AUTOSAR XML (schema 3.1.2)
package /Components/SWC_ProdElEng
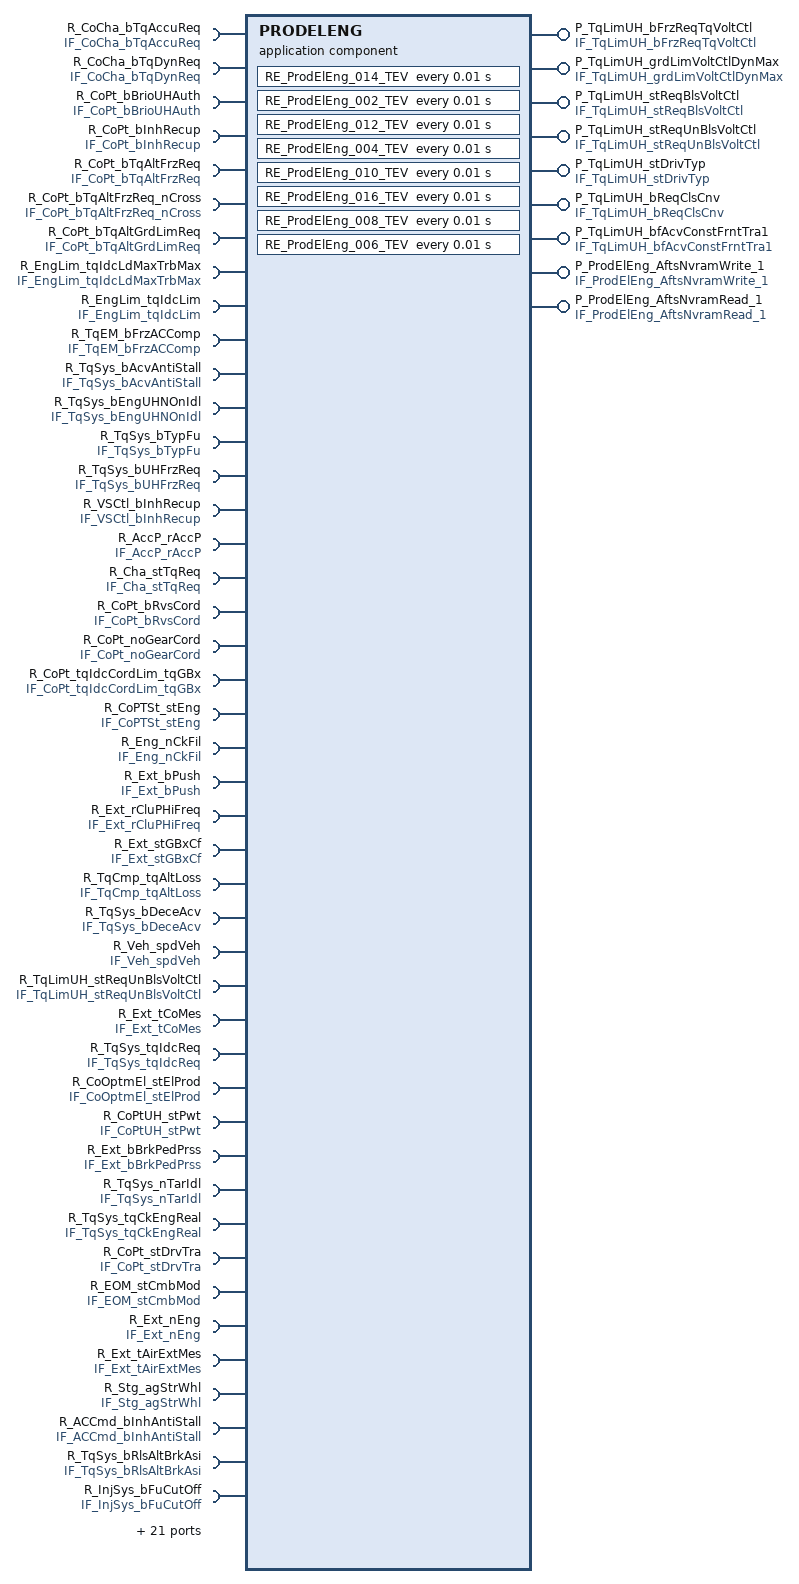
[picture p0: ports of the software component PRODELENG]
  application software component type PRODELENG
    63 x require port:
      R_CoCha_bTqAccuReq: unqueued-receiver-com-spec{data-element=CoCha_bTqAccuReq, init-value=ConstantValue, resync-time=0}, required-interface=IF_CoCha_bTqAccuReq
      R_CoCha_bTqDynReq: unqueued-receiver-com-spec{data-element=CoCha_bTqDynReq, init-value=ConstantValue1, resync-time=0}, required-interface=IF_CoCha_bTqDynReq
      R_CoPt_bBrioUHAuth: unqueued-receiver-com-spec{data-element=CoPt_bBrioUHAuth, init-value=CoPt_bBrioUHAuth_in, resync-time=0}, required-interface=IF_CoPt_bBrioUHAuth
      R_CoPt_bInhRecup: unqueued-receiver-com-spec{data-element=CoPt_bInhRecup, init-value=CoPt_bInhRecup_in, resync-time=0}, required-interface=IF_CoPt_bInhRecup
      R_CoPt_bTqAltFrzReq: unqueued-receiver-com-spec{data-element=CoPt_bTqAltFrzReq, init-value=CoPt_bTqAltFrzReq_in, resync-time=0}, required-interface=IF_CoPt_bTqAltFrzReq
      R_CoPt_bTqAltFrzReq_nCross: unqueued-receiver-com-spec{data-element=CoPt_bTqAltFrzReq_nCross, init-value=CoPt_bTqAltFrzReq_nCross_in, resync-time=0}, required-interface=IF_CoPt_bTqAltFrzReq_nCross
      R_CoPt_bTqAltGrdLimReq: unqueued-receiver-com-spec{data-element=CoPt_bTqAltGrdLimReq, init-value=CoPt_bTqAltGrdLimReq_in, resync-time=0}, required-interface=IF_CoPt_bTqAltGrdLimReq
      R_EngLim_tqIdcLdMaxTrbMax: unqueued-receiver-com-spec{data-element=EngLim_tqIdcLdMaxTrbMax, init-value=ConstantValue3, resync-time=0}, required-interface=IF_EngLim_tqIdcLdMaxTrbMax
      R_EngLim_tqIdcLim: unqueued-receiver-com-spec{data-element=EngLim_tqIdcLim, init-value=ConstantValue5, resync-time=0}, required-interface=IF_EngLim_tqIdcLim
      R_TqEM_bFrzACComp: unqueued-receiver-com-spec{data-element=TqEM_bFrzACComp, init-value=ConstantValue7, resync-time=0}, required-interface=IF_TqEM_bFrzACComp
      R_TqSys_bAcvAntiStall: unqueued-receiver-com-spec{data-element=TqSys_bAcvAntiStall, init-value=ConstantValue9, resync-time=0}, required-interface=IF_TqSys_bAcvAntiStall
      R_TqSys_bEngUHNOnIdl: unqueued-receiver-com-spec{data-element=TqSys_bEngUHNOnIdl, init-value=ConstantValue11, resync-time=0}, required-interface=IF_TqSys_bEngUHNOnIdl
      R_TqSys_bTypFu: unqueued-receiver-com-spec{data-element=TqSys_bTypFu, init-value=ConstantValue13, resync-time=0}, required-interface=IF_TqSys_bTypFu
      R_TqSys_bUHFrzReq: unqueued-receiver-com-spec{data-element=TqSys_bUHFrzReq, init-value=ConstantValue15, resync-time=0}, required-interface=IF_TqSys_bUHFrzReq
      R_VSCtl_bInhRecup: unqueued-receiver-com-spec{data-element=VSCtl_bInhRecup, init-value=VSCtl_bInhRecup_in, resync-time=0}, required-interface=IF_VSCtl_bInhRecup
      R_AccP_rAccP: unqueued-receiver-com-spec{data-element=AccP_rAccP, init-value=ConstantValue17, resync-time=0}, required-interface=IF_AccP_rAccP
      R_Cha_stTqReq: unqueued-receiver-com-spec{data-element=Cha_stTqReq, init-value=ConstantValue19, resync-time=0}, required-interface=IF_Cha_stTqReq
      R_CoPt_bRvsCord: unqueued-receiver-com-spec{data-element=CoPt_bRvsCord, init-value=ConstantValue21, resync-time=0}, required-interface=IF_CoPt_bRvsCord
      R_CoPt_noGearCord: unqueued-receiver-com-spec{data-element=CoPt_noGearCord, init-value=ConstantValue23, resync-time=0}, required-interface=IF_CoPt_noGearCord
      R_CoPt_tqIdcCordLim_tqGBx: unqueued-receiver-com-spec{data-element=CoPt_tqIdcCordLim_tqGBx, init-value=ConstantValue25, resync-time=0}, required-interface=IF_CoPt_tqIdcCordLim_tqGBx
      R_CoPTSt_stEng: unqueued-receiver-com-spec{data-element=CoPTSt_stEng, init-value=ConstantValue27, resync-time=0}, required-interface=IF_CoPTSt_stEng
      R_Eng_nCkFil: unqueued-receiver-com-spec{data-element=Eng_nCkFil, init-value=ConstantValue29, resync-time=0}, required-interface=IF_Eng_nCkFil
      R_Ext_bPush: unqueued-receiver-com-spec{data-element=Ext_bPush, init-value=ConstantValue31, resync-time=0}, required-interface=IF_Ext_bPush
      R_Ext_rCluPHiFreq: unqueued-receiver-com-spec{data-element=Ext_rCluPHiFreq, init-value=ConstantValue33, resync-time=0}, required-interface=IF_Ext_rCluPHiFreq
      R_Ext_stGBxCf: unqueued-receiver-com-spec{data-element=Ext_stGBxCf, init-value=ConstantValue35, resync-time=0}, required-interface=IF_Ext_stGBxCf
      R_TqCmp_tqAltLoss: unqueued-receiver-com-spec{data-element=TqCmp_tqAltLoss, init-value=ConstantValue37, resync-time=0}, required-interface=IF_TqCmp_tqAltLoss
      R_TqSys_bDeceAcv: unqueued-receiver-com-spec{data-element=TqSys_bDeceAcv, init-value=ConstantValue39, resync-time=0}, required-interface=IF_TqSys_bDeceAcv
      R_Veh_spdVeh: unqueued-receiver-com-spec{data-element=Veh_spdVeh, init-value=ConstantValue41, resync-time=0}, required-interface=IF_Veh_spdVeh
      R_TqLimUH_stReqUnBlsVoltCtl: unqueued-receiver-com-spec{data-element=TqLimUH_stReqUnBlsVoltCtl, init-value=ConstantValue43, resync-time=0}, required-interface=IF_TqLimUH_stReqUnBlsVoltCtl
      R_Ext_tCoMes: unqueued-receiver-com-spec{data-element=Ext_tCoMes, init-value=ConstantValue45, resync-time=0}, required-interface=IF_Ext_tCoMes
      R_TqSys_tqIdcReq: unqueued-receiver-com-spec{data-element=TqSys_tqIdcReq, init-value=ConstantValue47, resync-time=0}, required-interface=IF_TqSys_tqIdcReq
      R_CoOptmEl_stElProd: unqueued-receiver-com-spec{data-element=CoOptmEl_stElProd, init-value=ConstantValue49, resync-time=0}, required-interface=IF_CoOptmEl_stElProd
      R_CoPtUH_stPwt: unqueued-receiver-com-spec{data-element=CoPtUH_stPwt, init-value=ConstantValue51, resync-time=0}, required-interface=IF_CoPtUH_stPwt
      R_Ext_bBrkPedPrss: unqueued-receiver-com-spec{data-element=Ext_bBrkPedPrss, init-value=ConstantValue53, resync-time=0}, required-interface=IF_Ext_bBrkPedPrss
      R_TqSys_nTarIdl: unqueued-receiver-com-spec{data-element=TqSys_nTarIdl, init-value=ConstantValue55, resync-time=0}, required-interface=IF_TqSys_nTarIdl
      R_TqSys_tqCkEngReal: unqueued-receiver-com-spec{data-element=TqSys_tqCkEngReal, init-value=ConstantValue57, resync-time=0}, required-interface=IF_TqSys_tqCkEngReal
      R_CoPt_stDrvTra: unqueued-receiver-com-spec{data-element=CoPt_stDrvTra, init-value=ConstantValue59, resync-time=0}, required-interface=IF_CoPt_stDrvTra
      R_EOM_stCmbMod: unqueued-receiver-com-spec{data-element=EOM_stCmbMod, init-value=EOM_stCmbMod_in, resync-time=0}, required-interface=IF_EOM_stCmbMod
      R_Ext_nEng: unqueued-receiver-com-spec{data-element=Ext_nEng, init-value=ConstantValue61, resync-time=0}, required-interface=IF_Ext_nEng
      R_Ext_tAirExtMes: unqueued-receiver-com-spec{data-element=Ext_tAirExtMes, init-value=Ext_tAirExtMes_in, resync-time=0}, required-interface=IF_Ext_tAirExtMes
      R_Stg_agStrWhl: unqueued-receiver-com-spec{data-element=Stg_agStrWhl, init-value=Stg_agStrWhl_in, resync-time=0}, required-interface=IF_Stg_agStrWhl
      R_ACCmd_bInhAntiStall: unqueued-receiver-com-spec{data-element=ACCmd_bInhAntiStall, init-value=ConstantValue63, resync-time=0}, required-interface=IF_ACCmd_bInhAntiStall
      R_TqSys_bRlsAltBrkAsi: unqueued-receiver-com-spec{data-element=TqSys_bRlsAltBrkAsi, init-value=TqSys_bRlsAltBrkAsi_in, resync-time=0}, required-interface=IF_TqSys_bRlsAltBrkAsi
      R_InjSys_bFuCutOff: unqueued-receiver-com-spec{data-element=InjSys_bFuCutOff, init-value=ConstantValue65, resync-time=0}, required-interface=IF_InjSys_bFuCutOff
      R_CoVSCtl_rAccPEngTrv: unqueued-receiver-com-spec{data-element=CoVSCtl_rAccPEngTrv, init-value=ConstantValue67, resync-time=0}, required-interface=IF_CoVSCtl_rAccPEngTrv
      R_TqSys_tqCkEfcFilTrv: unqueued-receiver-com-spec{data-element=TqSys_tqCkEfcFilTrv, init-value=ConstantValue69, resync-time=0}, required-interface=IF_TqSys_tqCkEfcFilTrv
      R_EngLim_tqIdcFLdLim: unqueued-receiver-com-spec{data-element=EngLim_tqIdcFLdLim, init-value=ConstantValue71, resync-time=0}, required-interface=IF_EngLim_tqIdcFLdLim
      R_InjSP_mfFuPoI1Req: unqueued-receiver-com-spec{data-element=InjSP_mfFuPoI1Req, init-value=InjSP_mfFuPoI1Req_in, resync-time=0}, required-interface=IF_InjSP_mfFuPoI1Req
      R_InjSP_mfFuPoI2Req: unqueued-receiver-com-spec{data-element=InjSP_mfFuPoI2Req, init-value=InjSP_mfFuPoI2Req_in, resync-time=0}, required-interface=IF_InjSP_mfFuPoI2Req
      R_CoPt_bTqTx: unqueued-receiver-com-spec{data-element=CoPt_bTqTx, init-value=ConstantValue73, resync-time=0}, required-interface=IF_CoPt_bTqTx
      R_CoPt_stCnvCluFil: unqueued-receiver-com-spec{data-element=CoPt_stCnvCluFil, init-value=CoPt_stCnvCluFil_in, resync-time=0}, required-interface=IF_CoPt_stCnvCluFil
      R_CoPt_stCpl: unqueued-receiver-com-spec{data-element=CoPt_stCpl, init-value=ConstantValue75, resync-time=0}, required-interface=IF_CoPt_stCpl
      R_Ext_dstVehTotMes: unqueued-receiver-com-spec{data-element=Ext_dstVehTotMes, init-value=ConstantValue77, resync-time=0}, required-interface=IF_Ext_dstVehTotMes
      R_CoPt_stVoltAltBoostReq: unqueued-receiver-com-spec{data-element=CoPt_stVoltAltBoostReq, init-value=CoPt_stVoltAltBoostReq_in, resync-time=0}, required-interface=IF_CoPt_stVoltAltBoostReq
      R_FRM_bInhTqLimUHBrioUH: required-interface=FunctionInhibition
      R_FRM_bAcvTqLimUHMdl_tqGrdLim: required-interface=FunctionInhibition
      R_FRM_bInhRecupUH: required-interface=FunctionInhibition
      R_FRM_bInhRecupVoltCtl: required-interface=FunctionInhibition
      R_FRM_bInhWup: required-interface=FunctionInhibition
      R_FRM_bInhTqLimUHAntiStall: required-interface=FunctionInhibition
      R_FRM_bDrivTyp: required-interface=FunctionInhibition
      R_FRM_bInhTqLimUHTqMchFrz: required-interface=FunctionInhibition
      R_FRM_bInhTqSysStInjEs: required-interface=FunctionInhibition
    7 x provide port:
      P_TqLimUH_bFrzReqTqVoltCtl: unqueued-sender-com-spec{data-element=TqLimUH_bFrzReqTqVoltCtl, can-invalidate=false, init-value=ConstantValue79}, provided-interface=IF_TqLimUH_bFrzReqTqVoltCtl
      P_TqLimUH_grdLimVoltCtlDynMax: unqueued-sender-com-spec{data-element=TqLimUH_grdLimVoltCtlDynMax, can-invalidate=false, init-value=ConstantValue81}, provided-interface=IF_TqLimUH_grdLimVoltCtlDynMax
      P_TqLimUH_stReqBlsVoltCtl: unqueued-sender-com-spec{data-element=TqLimUH_stReqBlsVoltCtl, can-invalidate=false, init-value=ConstantValue83}, provided-interface=IF_TqLimUH_stReqBlsVoltCtl
      P_TqLimUH_stReqUnBlsVoltCtl: unqueued-sender-com-spec{data-element=TqLimUH_stReqUnBlsVoltCtl, can-invalidate=false, init-value=ConstantValue85}, provided-interface=IF_TqLimUH_stReqUnBlsVoltCtl
      P_TqLimUH_stDrivTyp: unqueued-sender-com-spec{data-element=TqLimUH_stDrivTyp, can-invalidate=false, init-value=ConstantValue87}, provided-interface=IF_TqLimUH_stDrivTyp
      P_TqLimUH_bReqClsCnv: unqueued-sender-com-spec{data-element=TqLimUH_bReqClsCnv, can-invalidate=false, init-value=TqLimUH_bReqClsCnv_out}, provided-interface=IF_TqLimUH_bReqClsCnv
      P_TqLimUH_bfAcvConstFrntTra1: unqueued-sender-com-spec{data-element=TqLimUH_bfAcvConstFrntTra1, can-invalidate=false, init-value=ConstantValue89}, provided-interface=IF_TqLimUH_bfAcvConstFrntTra1
    require port R_UCE_stWkuMainRelSt: required-interface=IF_UCE_stWkuMainRelSt
    require port R_EcuM_CurrentMode: required-interface=EcuM_CurrentMode
    provide port P_ProdElEng_AftsNvramWrite_1: server-com-spec{operation=op_ProdElEng_AftsNvramWrite_1, queue-length=1}, provided-interface=IF_ProdElEng_AftsNvramWrite_1
    provide port P_ProdElEng_AftsNvramRead_1: server-com-spec{operation=op_ProdElEng_AftsNvramRead_1, queue-length=1}, provided-interface=IF_ProdElEng_AftsNvramRead_1
  85 x constant specification:
    ConstantValue
      value:
        boolean literal ConstantValue: type=DT_CoCha_bTqAccuReq, value=false
    ConstantValue1
      value:
        boolean literal ConstantValue1: type=DT_CoCha_bTqDynReq, value=false
    ConstantValue11
      value:
        boolean literal ConstantValue11: type=DT_TqSys_bEngUHNOnIdl, value=true
    ConstantValue13
      value:
        boolean literal ConstantValue13: type=DT_TqSys_bTypFu, value=false
    ConstantValue15
      value:
        boolean literal ConstantValue15: type=DT_TqSys_bUHFrzReq, value=false
    ConstantValue17
      value:
        integer literal ConstantValue17: type=DT_AccP_rAccP, value=0
    ConstantValue19
      value:
        integer literal ConstantValue19: type=DT_Cha_stTqReq, value=0
    ConstantValue21
      value:
        boolean literal ConstantValue21: type=DT_CoPt_bRvsCord, value=false
    ConstantValue23
      value:
        integer literal ConstantValue23: type=DT_CoPt_noGearCord, value=0
    ConstantValue25
      value:
        integer literal ConstantValue25: type=DT_CoPt_tqIdcCordLim_tqGBx, value=0
    ConstantValue27
      value:
        integer literal ConstantValue27: type=DT_CoPTSt_stEng, value=1
    ConstantValue29
      value:
        integer literal ConstantValue29: type=DT_Eng_nCkFil, value=0
    ConstantValue3
      value:
        integer literal ConstantValue3: type=DT_EngLim_tqIdcLdMaxTrbMax, value=32000
    ConstantValue31
      value:
        boolean literal ConstantValue31: type=DT_Ext_bPush, value=false
    ConstantValue33
      value:
        integer literal ConstantValue33: type=DT_Ext_rCluPHiFreq, value=0
    ConstantValue35
      value:
        integer literal ConstantValue35: type=DT_Ext_stGBxCf, value=0
    ConstantValue37
      value:
        integer literal ConstantValue37: type=DT_TqCmp_tqAltLoss, value=0
    ConstantValue39
      value:
        boolean literal ConstantValue39: type=DT_TqSys_bDeceAcv, value=false
    ConstantValue41
      value:
        integer literal ConstantValue41: type=DT_Veh_spdVeh, value=0
    ConstantValue43
      value:
        integer literal ConstantValue43: type=DT_TqLimUH_stReqUnBlsVoltCtl, value=0
    ConstantValue45
      value:
        integer literal ConstantValue45: type=DT_Ext_tCoMes, value=20
    ConstantValue47
      value:
        integer literal ConstantValue47: type=DT_TqSys_tqIdcReq, value=0
    ConstantValue49
      value:
        integer literal ConstantValue49: type=DT_CoOptmEl_stElProd, value=0
    ConstantValue5
      value:
        integer literal ConstantValue5: type=DT_EngLim_tqIdcLim, value=32000
    ConstantValue51
      value:
        integer literal ConstantValue51: type=DT_CoPtUH_stPwt, value=1
    ConstantValue53
      value:
        boolean literal ConstantValue53: type=DT_Ext_bBrkPedPrss, value=false
    ConstantValue55
      value:
        integer literal ConstantValue55: type=DT_TqSys_nTarIdl, value=0
    ConstantValue57
      value:
        integer literal ConstantValue57: type=DT_TqSys_tqCkEngReal, value=0
    ConstantValue59
      value:
        boolean literal ConstantValue59: type=DT_CoPt_stDrvTra, value=false
    ConstantValue61
      value:
        integer literal ConstantValue61: type=DT_Ext_nEng, value=0
    ConstantValue63
      value:
        boolean literal ConstantValue63: type=DT_ACCmd_bInhAntiStall, value=false
    ConstantValue65
      value:
        boolean literal ConstantValue65: type=DT_InjSys_bFuCutOff, value=false
    ConstantValue67
      value:
        integer literal ConstantValue67: type=DT_CoVSCtl_rAccPEngTrv, value=0
    ConstantValue69
      value:
        integer literal ConstantValue69: type=DT_TqSys_tqCkEfcFilTrv, value=0
    ConstantValue7
      value:
        boolean literal ConstantValue7: type=DT_TqEM_bFrzACComp, value=false
    ConstantValue71
      value:
        integer literal ConstantValue71: type=DT_EngLim_tqIdcFLdLim, value=32000
    ConstantValue73
      value:
        boolean literal ConstantValue73: type=DT_CoPt_bTqTx, value=false
    ConstantValue75
      value:
        integer literal ConstantValue75: type=DT_CoPt_stCpl, value=0
    ConstantValue77
      value:
        integer literal ConstantValue77: type=DT_Ext_dstVehTotMes, value=0
    ConstantValue79
      value:
        boolean literal ConstantValue79: type=DT_TqLimUH_bFrzReqTqVoltCtl, value=false
    ConstantValue81
      value:
        integer literal ConstantValue81: type=DT_TqLimUH_grdLimVoltCtlDynMax, value=4
    ConstantValue83
      value:
        integer literal ConstantValue83: type=DT_TqLimUH_stReqBlsVoltCtl, value=0
    ConstantValue85
      value:
        integer literal ConstantValue85: type=DT_TqLimUH_stReqUnBlsVoltCtl, value=0
    ConstantValue87
      value:
        integer literal ConstantValue87: type=DT_TqLimUH_stDrivTyp, value=0
    ConstantValue89
      value:
        integer literal ConstantValue89: type=DT_TqLimUH_bfAcvConstFrntTra1, value=0
    ConstantValue9
      value:
        boolean literal ConstantValue9: type=DT_TqSys_bAcvAntiStall, value=true
    CoPt_bBrioUHAuth_in
      value:
        boolean literal CoPt_bBrioUHAuth_in: type=DT_CoPt_bBrioUHAuth, value=false
    CoPt_bInhRecup_in
      value:
        boolean literal CoPt_bInhRecup_in: type=DT_CoPt_bInhRecup, value=false
    CoPt_bTqAltFrzReq_in
      value:
        boolean literal CoPt_bTqAltFrzReq_in: type=DT_CoPt_bTqAltFrzReq, value=false
    CoPt_bTqAltFrzReq_nCross_in
      value:
        boolean literal CoPt_bTqAltFrzReq_nCross_in: type=DT_CoPt_bTqAltFrzReq_nCross, value=false
    CoPt_bTqAltGrdLimReq_in
      value:
        boolean literal CoPt_bTqAltGrdLimReq_in: type=DT_CoPt_bTqAltGrdLimReq, value=false
    CoPt_stCnvCluFil_in
      value:
        integer literal CoPt_stCnvCluFil_in: type=DT_CoPt_stCnvCluFil, value=0
    CoPt_stVoltAltBoostReq_in
      value:
        integer literal CoPt_stVoltAltBoostReq_in: type=DT_CoPt_stVoltAltBoostReq, value=0
    EOM_stCmbMod_in
      value:
        integer literal EOM_stCmbMod_in: type=DT_EOM_stCmbMod, value=3
    Ext_tAirExtMes_in
      value:
        integer literal Ext_tAirExtMes_in: type=DT_Ext_tAirExtMes, value=20
    InjSP_mfFuPoI1Req_in
      value:
        integer literal InjSP_mfFuPoI1Req_in: type=DT_InjSP_mfFuPoI1Req, value=0
    InjSP_mfFuPoI2Req_in
      value:
        integer literal InjSP_mfFuPoI2Req_in: type=DT_InjSP_mfFuPoI2Req, value=0
    Stg_agStrWhl_in
      value:
        integer literal Stg_agStrWhl_in: type=DT_Stg_agStrWhl, value=-7800
    TqLimUH_bAcvAntiStall_Cst
      value:
        boolean literal TqLimUH_bAcvAntiStall_Cst: type=DT_TqLimUH_bAcvAntiStall, value=false
    TqLimUH_bAntiStall_Cst
      value:
        boolean literal TqLimUH_bAntiStall_Cst: type=DT_TqLimUH_bAntiStall, value=false
    TqLimUH_bAntiStallGrdUnlim_Cst
      value:
        boolean literal TqLimUH_bAntiStallGrdUnlim_Cst: type=DT_TqLimUH_bAntiStallGrdUnlim, value=false
    TqLimUH_bBrioUHBoost_Cst
      value:
        boolean literal TqLimUH_bBrioUHBoost_Cst: type=DT_TqLimUH_bBrioUHBoost, value=false
    TqLimUH_bBrioUHGrdUnlim_Cst
      value:
        boolean literal TqLimUH_bBrioUHGrdUnlim_Cst: type=DT_TqLimUH_bBrioUHGrdUnlim, value=false
    TqLimUH_bBrioUHRls_Cst
      value:
        boolean literal TqLimUH_bBrioUHRls_Cst: type=DT_TqLimUH_bBrioUHRls, value=false
    TqLimUH_bEngUHNOnIdl_Cst
      value:
        boolean literal TqLimUH_bEngUHNOnIdl_Cst: type=DT_TqLimUH_bEngUHNOnIdl, value=false
    TqLimUH_bESPUnBlsAltReq_Cst
      value:
        boolean literal TqLimUH_bESPUnBlsAltReq_Cst: type=DT_TqLimUH_bESPUnBlsAltReq, value=false
    TqLimUH_bOutFrzUHGrdLim_Cst
      value:
        boolean literal TqLimUH_bOutFrzUHGrdLim_Cst: type=DT_TqLimUH_bOutFrzUHGrdLim, value=false
    TqLimUH_bRecupAcv_Cst
      value:
        boolean literal TqLimUH_bRecupAcv_Cst: type=DT_TqLimUH_bRecupAcv, value=false
    TqLimUH_bReqClsCnv_out
      value:
        boolean literal TqLimUH_bReqClsCnv_out: type=DT_TqLimUH_bReqClsCnv, value=false
    TqLimUH_bRlsAltBrkAsi_Cst
      value:
        boolean literal TqLimUH_bRlsAltBrkAsi_Cst: type=DT_TqLimUH_bRlsAltBrkAsi, value=false
    TqLimUH_bTqAltFrzReq_Cst
      value:
        boolean literal TqLimUH_bTqAltFrzReq_Cst: type=DT_TqLimUH_bTqAltFrzReq, value=false
    TqLimUH_bUHRecupInh_Cst
      value:
        boolean literal TqLimUH_bUHRecupInh_Cst: type=DT_TqLimUH_bUHRecupInh, value=false
    TqLimUH_tqGrdBrioUHJerkLim_Cst
      value:
        integer literal TqLimUH_tqGrdBrioUHJerkLim_Cst: type=DT_TqLimUH_tqGrdBrioUHJerkLim, value=254
    TqLimUH_tqGrdLimUHDynMax_Cst
      value:
        integer literal TqLimUH_tqGrdLimUHDynMax_Cst: type=DT_TqLimUH_tqGrdLimUHDynMax, value=40
    TqLimUH_tqIdcFLdLim_Cst
      value:
        integer literal TqLimUH_tqIdcFLdLim_Cst: type=DT_TqLimUH_tqIdcFLdLim, value=0
    TqLimUH_tqIdcMaxLim_Cst
      value:
        integer literal TqLimUH_tqIdcMaxLim_Cst: type=DT_TqLimUH_tqIdcMaxLim, value=0
    TqSys_bBrioUHAuth_Cst
      value:
        boolean literal TqSys_bBrioUHAuth_Cst: type=DT_TqSys_bBrioUHAuth, value=false
    TqSys_bInhRecupUHVoltCtl_Cst
      value:
        boolean literal TqSys_bInhRecupUHVoltCtl_Cst: type=DT_TqSys_bInhRecupUHVoltCtl, value=false
    TqSys_bInjAcvUHReq_Cst
      value:
        boolean literal TqSys_bInjAcvUHReq_Cst: type=DT_TqSys_bInjAcvUHReq, value=true
    TqSys_bInjFrzTqUHReq_Cst
      value:
        boolean literal TqSys_bInjFrzTqUHReq_Cst: type=DT_TqSys_bInjFrzTqUHReq, value=false
    TqSys_bRlsAltBrkAsi_in
      value:
        boolean literal TqSys_bRlsAltBrkAsi_in: type=DT_TqSys_bRlsAltBrkAsi, value=false
    TqSys_bTqAltFrzReq_Cst
      value:
        boolean literal TqSys_bTqAltFrzReq_Cst: type=DT_TqSys_bTqAltFrzReq, value=false
    TqSys_bTqAltGrdLimReq_Cst
      value:
        boolean literal TqSys_bTqAltGrdLimReq_Cst: type=DT_TqSys_bTqAltGrdLimReq, value=false
    TqSys_bTqAltRlsReq_Cst
      value:
        boolean literal TqSys_bTqAltRlsReq_Cst: type=DT_TqSys_bTqAltRlsReq, value=false
    VSCtl_bInhRecup_in
      value:
        boolean literal VSCtl_bInhRecup_in: type=DT_VSCtl_bInhRecup, value=false
  internal behavior IB_ProdElEng: component=PRODELENG
    mode switch event EV_ProdElEng_001_MSE: start-on-event=RE_ProdElEng_001_MSE, activation=ENTRY, mode=R_EcuM_CurrentMode.currentMode.RUN
    timing event EV_ProdElEng_014_TEV: mode-dependency=dependent-on-mode=[R_UCE_stWkuMainRelSt.RCD_stWkuMainRelSt.PreMainWakeUp, R_UCE_stWkuMainRelSt.RCD_stWkuMainRelSt.PostMainWakeUp, R_UCE_stWkuMainRelSt.RCD_stWkuMainRelSt.Invalid], start-on-event=RE_ProdElEng_014_TEV, period=0.01
    mode switch event EV_ProdElEng_013_MSE: start-on-event=RE_ProdElEng_013_MSE, activation=ENTRY, mode=R_EcuM_CurrentMode.currentMode.RUN
    mode switch event EV_ProdElEng_009_MSE: start-on-event=RE_ProdElEng_009_MSE, activation=ENTRY, mode=R_EcuM_CurrentMode.currentMode.RUN
    mode switch event EV_ProdElEng_003_MSE: start-on-event=RE_ProdElEng_003_MSE, activation=ENTRY, mode=R_EcuM_CurrentMode.currentMode.RUN
    timing event EV_ProdElEng_002_TEV: mode-dependency=dependent-on-mode=[R_UCE_stWkuMainRelSt.RCD_stWkuMainRelSt.PreMainWakeUp, R_UCE_stWkuMainRelSt.RCD_stWkuMainRelSt.PostMainWakeUp, R_UCE_stWkuMainRelSt.RCD_stWkuMainRelSt.Invalid], start-on-event=RE_ProdElEng_002_TEV, period=0.01
    mode switch event EV_ProdElEng_015_MSE: start-on-event=RE_ProdElEng_015_MSE, activation=ENTRY, mode=R_EcuM_CurrentMode.currentMode.RUN
    mode switch event EV_ProdElEng_005_MSE: start-on-event=RE_ProdElEng_005_MSE, activation=ENTRY, mode=R_EcuM_CurrentMode.currentMode.RUN
    timing event EV_ProdElEng_012_TEV: mode-dependency=dependent-on-mode=[R_UCE_stWkuMainRelSt.RCD_stWkuMainRelSt.PreMainWakeUp, R_UCE_stWkuMainRelSt.RCD_stWkuMainRelSt.PostMainWakeUp, R_UCE_stWkuMainRelSt.RCD_stWkuMainRelSt.Invalid], start-on-event=RE_ProdElEng_012_TEV, period=0.01
    operation invoked event EV_ProdElEng_AftsNvramRead_1: start-on-event=RE_ProdElEng_AftsNvramRead_1, operation=P_ProdElEng_AftsNvramRead_1.op_ProdElEng_AftsNvramRead_1
    timing event EV_ProdElEng_004_TEV: mode-dependency=dependent-on-mode=[R_UCE_stWkuMainRelSt.RCD_stWkuMainRelSt.PreMainWakeUp, R_UCE_stWkuMainRelSt.RCD_stWkuMainRelSt.PostMainWakeUp, R_UCE_stWkuMainRelSt.RCD_stWkuMainRelSt.Invalid], start-on-event=RE_ProdElEng_004_TEV, period=0.01
    mode switch event EV_ProdElEng_007_MSE: start-on-event=RE_ProdElEng_007_MSE, activation=ENTRY, mode=R_EcuM_CurrentMode.currentMode.RUN
    operation invoked event EV_ProdElEng_AftsNvramWrite_1: start-on-event=RE_ProdElEng_AftsNvramWrite_1, operation=P_ProdElEng_AftsNvramWrite_1.op_ProdElEng_AftsNvramWrite_1
    timing event EV_ProdElEng_010_TEV: mode-dependency=dependent-on-mode=[R_UCE_stWkuMainRelSt.RCD_stWkuMainRelSt.PreMainWakeUp, R_UCE_stWkuMainRelSt.RCD_stWkuMainRelSt.PostMainWakeUp, R_UCE_stWkuMainRelSt.RCD_stWkuMainRelSt.Invalid], start-on-event=RE_ProdElEng_010_TEV, period=0.01
    timing event EV_ProdElEng_016_TEV: mode-dependency=dependent-on-mode=[R_UCE_stWkuMainRelSt.RCD_stWkuMainRelSt.PreMainWakeUp, R_UCE_stWkuMainRelSt.RCD_stWkuMainRelSt.PostMainWakeUp, R_UCE_stWkuMainRelSt.RCD_stWkuMainRelSt.Invalid], start-on-event=RE_ProdElEng_016_TEV, period=0.01
    mode switch event EV_ProdElEng_011_MSE: start-on-event=RE_ProdElEng_011_MSE, activation=ENTRY, mode=R_EcuM_CurrentMode.currentMode.RUN
    timing event EV_ProdElEng_008_TEV: mode-dependency=dependent-on-mode=[R_UCE_stWkuMainRelSt.RCD_stWkuMainRelSt.PreMainWakeUp, R_UCE_stWkuMainRelSt.RCD_stWkuMainRelSt.PostMainWakeUp, R_UCE_stWkuMainRelSt.RCD_stWkuMainRelSt.Invalid], start-on-event=RE_ProdElEng_008_TEV, period=0.01
    timing event EV_ProdElEng_006_TEV: mode-dependency=dependent-on-mode=[R_UCE_stWkuMainRelSt.RCD_stWkuMainRelSt.PreMainWakeUp, R_UCE_stWkuMainRelSt.RCD_stWkuMainRelSt.PostMainWakeUp, R_UCE_stWkuMainRelSt.RCD_stWkuMainRelSt.Invalid], start-on-event=RE_ProdElEng_006_TEV, period=0.01
    24 x inter runnable variable, all with sw-calibration-access=READ-WRITE, communication-approach=EXPLICIT:
      TqSys_bTqAltFrzReq: type=DT_TqSys_bTqAltFrzReq, init-value=TqSys_bTqAltFrzReq_Cst
      TqLimUH_bRecupAcv: type=DT_TqLimUH_bRecupAcv, init-value=TqLimUH_bRecupAcv_Cst
      TqLimUH_bBrioUHBoost: type=DT_TqLimUH_bBrioUHBoost, init-value=TqLimUH_bBrioUHBoost_Cst
      TqSys_bInjFrzTqUHReq: type=DT_TqSys_bInjFrzTqUHReq, init-value=TqSys_bInjFrzTqUHReq_Cst
      TqLimUH_bRlsAltBrkAsi: type=DT_TqLimUH_bRlsAltBrkAsi, init-value=TqLimUH_bRlsAltBrkAsi_Cst
      TqLimUH_bTqAltFrzReq: type=DT_TqLimUH_bTqAltFrzReq, init-value=TqLimUH_bTqAltFrzReq_Cst
      TqSys_bTqAltRlsReq: type=DT_TqSys_bTqAltRlsReq, init-value=TqSys_bTqAltRlsReq_Cst
      TqSys_bTqAltGrdLimReq: type=DT_TqSys_bTqAltGrdLimReq, init-value=TqSys_bTqAltGrdLimReq_Cst
      TqLimUH_tqGrdBrioUHJerkLim: type=DT_TqLimUH_tqGrdBrioUHJerkLim, init-value=TqLimUH_tqGrdBrioUHJerkLim_Cst
      TqLimUH_tqIdcFLdLim: type=DT_TqLimUH_tqIdcFLdLim, init-value=TqLimUH_tqIdcFLdLim_Cst
      TqLimUH_bAntiStallGrdUnlim: type=DT_TqLimUH_bAntiStallGrdUnlim, init-value=TqLimUH_bAntiStallGrdUnlim_Cst
      TqSys_bBrioUHAuth: type=DT_TqSys_bBrioUHAuth, init-value=TqSys_bBrioUHAuth_Cst
      TqLimUH_bEngUHNOnIdl: type=DT_TqLimUH_bEngUHNOnIdl, init-value=TqLimUH_bEngUHNOnIdl_Cst
      TqLimUH_bBrioUHGrdUnlim: type=DT_TqLimUH_bBrioUHGrdUnlim, init-value=TqLimUH_bBrioUHGrdUnlim_Cst
      TqLimUH_bAntiStall: type=DT_TqLimUH_bAntiStall, init-value=TqLimUH_bAntiStall_Cst
      TqLimUH_tqGrdLimUHDynMax: type=DT_TqLimUH_tqGrdLimUHDynMax, init-value=TqLimUH_tqGrdLimUHDynMax_Cst
      TqLimUH_bUHRecupInh: type=DT_TqLimUH_bUHRecupInh, init-value=TqLimUH_bUHRecupInh_Cst
      TqLimUH_bBrioUHRls: type=DT_TqLimUH_bBrioUHRls, init-value=TqLimUH_bBrioUHRls_Cst
      TqLimUH_bAcvAntiStall: type=DT_TqLimUH_bAcvAntiStall, init-value=TqLimUH_bAcvAntiStall_Cst
      TqSys_bInjAcvUHReq: type=DT_TqSys_bInjAcvUHReq, init-value=TqSys_bInjAcvUHReq_Cst
      TqLimUH_tqIdcMaxLim: type=DT_TqLimUH_tqIdcMaxLim, init-value=TqLimUH_tqIdcMaxLim_Cst
      TqLimUH_bESPUnBlsAltReq: type=DT_TqLimUH_bESPUnBlsAltReq, init-value=TqLimUH_bESPUnBlsAltReq_Cst
      TqLimUH_bOutFrzUHGrdLim: type=DT_TqLimUH_bOutFrzUHGrdLim, init-value=TqLimUH_bOutFrzUHGrdLim_Cst
      TqSys_bInhRecupUHVoltCtl: type=DT_TqSys_bInhRecupUHVoltCtl, init-value=TqSys_bInhRecupUHVoltCtl_Cst
    18 x runnable:
      RE_ProdElEng_003_MSE: written-variable=[TqLimUH_bBrioUHBoost, TqLimUH_bBrioUHGrdUnlim, TqLimUH_bBrioUHRls, TqLimUH_tqGrdBrioUHJerkLim]
      RE_ProdElEng_007_MSE: written-variable=TqLimUH_tqGrdLimUHDynMax
      RE_ProdElEng_001_MSE: written-variable=[TqLimUH_tqIdcFLdLim, TqLimUH_bEngUHNOnIdl, TqSys_bBrioUHAuth, TqLimUH_bAcvAntiStall, TqLimUH_bRlsAltBrkAsi, TqSys_bInhRecupUHVoltCtl, TqSys_bTqAltRlsReq, TqSys_bTqAltGrdLimReq, TqLimUH_tqIdcMaxLim, TqSys_bTqAltFrzReq]
      RE_ProdElEng_005_MSE: written-variable=[TqLimUH_bTqAltFrzReq, TqLimUH_bESPUnBlsAltReq, TqLimUH_bOutFrzUHGrdLim]
      RE_ProdElEng_AftsNvramRead_1
      RE_ProdElEng_015_MSE: written-variable=[TqLimUH_bAntiStallGrdUnlim, TqLimUH_bAntiStall]
      RE_ProdElEng_006_TEV: read-variable=[TqSys_bTqAltRlsReq, TqSys_bTqAltFrzReq], written-variable=[TqLimUH_bOutFrzUHGrdLim, TqLimUH_bESPUnBlsAltReq, TqLimUH_bTqAltFrzReq]
        data receive point dr_TqLimUH_stReqUnBlsVoltCtl: data-element=R_TqLimUH_stReqUnBlsVoltCtl.TqLimUH_stReqUnBlsVoltCtl
        data receive point dr_TqCmp_tqAltLoss: data-element=R_TqCmp_tqAltLoss.TqCmp_tqAltLoss
        data receive point dr_CoPTSt_stEng: data-element=R_CoPTSt_stEng.CoPTSt_stEng
        sync call ssp_FRM_bInhTqLimUHTqMchFrz: operation=R_FRM_bInhTqLimUHTqMchFrz.GetFunctionPermission
      RE_ProdElEng_008_TEV: read-variable=[TqLimUH_bOutFrzUHGrdLim, TqLimUH_tqGrdBrioUHJerkLim, TqLimUH_bBrioUHGrdUnlim, TqLimUH_bRecupAcv, TqLimUH_bAntiStallGrdUnlim, TqSys_bTqAltGrdLimReq, TqLimUH_bEngUHNOnIdl, TqLimUH_bTqAltFrzReq], written-variable=TqLimUH_tqGrdLimUHDynMax
        5 x data receive point:
          dr_CoPt_noGearCord: data-element=R_CoPt_noGearCord.CoPt_noGearCord
          dr_TqCmp_tqAltLoss: data-element=R_TqCmp_tqAltLoss.TqCmp_tqAltLoss
          dr_Eng_nCkFil: data-element=R_Eng_nCkFil.Eng_nCkFil
          dr_Ext_tCoMes: data-element=R_Ext_tCoMes.Ext_tCoMes
          dr_CoPTSt_stEng: data-element=R_CoPTSt_stEng.CoPTSt_stEng
        sync call ssp_FRM_bAcvTqLimUHMdl_tqGrdLim: operation=R_FRM_bAcvTqLimUHMdl_tqGrdLim.GetFunctionPermission
      RE_ProdElEng_011_MSE: written-variable=[TqLimUH_bRecupAcv, TqLimUH_bUHRecupInh]
        6 x data send point:
          ds_TqLimUH_bFrzReqTqVoltCtl: data-element=P_TqLimUH_bFrzReqTqVoltCtl.TqLimUH_bFrzReqTqVoltCtl
          ds_TqLimUH_stReqBlsVoltCtl: data-element=P_TqLimUH_stReqBlsVoltCtl.TqLimUH_stReqBlsVoltCtl
          ds_TqLimUH_stReqUnBlsVoltCtl: data-element=P_TqLimUH_stReqUnBlsVoltCtl.TqLimUH_stReqUnBlsVoltCtl
          ds_TqLimUH_bReqClsCnv: data-element=P_TqLimUH_bReqClsCnv.TqLimUH_bReqClsCnv
          ds_TqLimUH_bfAcvConstFrntTra1: data-element=P_TqLimUH_bfAcvConstFrntTra1.TqLimUH_bfAcvConstFrntTra1
          ds_TqLimUH_grdLimVoltCtlDynMax: data-element=P_TqLimUH_grdLimVoltCtlDynMax.TqLimUH_grdLimVoltCtlDynMax
      RE_ProdElEng_016_TEV: read-variable=[TqLimUH_bAcvAntiStall, TqLimUH_bESPUnBlsAltReq], written-variable=[TqLimUH_bAntiStall, TqLimUH_bAntiStallGrdUnlim]
        data receive point dr_ACCmd_bInhAntiStall: data-element=R_ACCmd_bInhAntiStall.ACCmd_bInhAntiStall
        data receive point dr_CoPTSt_stEng: data-element=R_CoPTSt_stEng.CoPTSt_stEng
        sync call ssp_FRM_bInhTqLimUHAntiStall: operation=R_FRM_bInhTqLimUHAntiStall.GetFunctionPermission
      RE_ProdElEng_013_MSE
        data send point ds_TqLimUH_stDrivTyp: data-element=P_TqLimUH_stDrivTyp.TqLimUH_stDrivTyp
      RE_ProdElEng_002_TEV: read-variable=TqSys_bInjFrzTqUHReq, written-variable=[TqSys_bBrioUHAuth, TqLimUH_bEngUHNOnIdl, TqLimUH_bRlsAltBrkAsi, TqLimUH_tqIdcMaxLim, TqSys_bTqAltGrdLimReq, TqLimUH_tqIdcFLdLim, TqLimUH_bAcvAntiStall, TqSys_bTqAltRlsReq, TqSys_bInhRecupUHVoltCtl, TqSys_bTqAltFrzReq]
        17 x data receive point:
          dr_TqSys_bUHFrzReq: data-element=R_TqSys_bUHFrzReq.TqSys_bUHFrzReq
          dr_TqSys_bAcvAntiStall: data-element=R_TqSys_bAcvAntiStall.TqSys_bAcvAntiStall
          dr_CoCha_bTqAccuReq: data-element=R_CoCha_bTqAccuReq.CoCha_bTqAccuReq
          dr_CoPt_bBrioUHAuth: data-element=R_CoPt_bBrioUHAuth.CoPt_bBrioUHAuth
          dr_VSCtl_bInhRecup: data-element=R_VSCtl_bInhRecup.VSCtl_bInhRecup
          dr_CoPt_bTqAltGrdLimReq: data-element=R_CoPt_bTqAltGrdLimReq.CoPt_bTqAltGrdLimReq
          dr_CoPt_bInhRecup: data-element=R_CoPt_bInhRecup.CoPt_bInhRecup
          dr_EngLim_tqIdcFLdLim: data-element=R_EngLim_tqIdcFLdLim.EngLim_tqIdcFLdLim
          dr_TqEM_bFrzACComp: data-element=R_TqEM_bFrzACComp.TqEM_bFrzACComp
          dr_CoPt_bTqAltFrzReq: data-element=R_CoPt_bTqAltFrzReq.CoPt_bTqAltFrzReq
          dr_TqSys_bTypFu: data-element=R_TqSys_bTypFu.TqSys_bTypFu
          dr_CoPt_bTqAltFrzReq_nCross: data-element=R_CoPt_bTqAltFrzReq_nCross.CoPt_bTqAltFrzReq_nCross
          dr_TqSys_bEngUHNOnIdl: data-element=R_TqSys_bEngUHNOnIdl.TqSys_bEngUHNOnIdl
          dr_EngLim_tqIdcLdMaxTrbMax: data-element=R_EngLim_tqIdcLdMaxTrbMax.EngLim_tqIdcLdMaxTrbMax
          dr_EngLim_tqIdcLim: data-element=R_EngLim_tqIdcLim.EngLim_tqIdcLim
          dr_CoCha_bTqDynReq: data-element=R_CoCha_bTqDynReq.CoCha_bTqDynReq
          dr_TqSys_bRlsAltBrkAsi: data-element=R_TqSys_bRlsAltBrkAsi.TqSys_bRlsAltBrkAsi
      RE_ProdElEng_010_TEV: written-variable=[TqSys_bInjFrzTqUHReq, TqSys_bInjAcvUHReq]
        6 x data receive point:
          dr_Eng_nCkFil: data-element=R_Eng_nCkFil.Eng_nCkFil
          dr_TqSys_tqIdcReq: data-element=R_TqSys_tqIdcReq.TqSys_tqIdcReq
          dr_TqSys_bTypFu: data-element=R_TqSys_bTypFu.TqSys_bTypFu
          dr_InjSys_bFuCutOff: data-element=R_InjSys_bFuCutOff.InjSys_bFuCutOff
          dr_InjSP_mfFuPoI1Req: data-element=R_InjSP_mfFuPoI1Req.InjSP_mfFuPoI1Req
          dr_InjSP_mfFuPoI2Req: data-element=R_InjSP_mfFuPoI2Req.InjSP_mfFuPoI2Req
        sync call ssp_FRM_bInhTqSysStInjEs: operation=R_FRM_bInhTqSysStInjEs.GetFunctionPermission
      RE_ProdElEng_012_TEV: read-variable=[TqLimUH_bBrioUHBoost, TqLimUH_bBrioUHRls, TqLimUH_tqGrdLimUHDynMax, TqLimUH_bTqAltFrzReq, TqSys_bInhRecupUHVoltCtl, TqLimUH_bAntiStall, TqSys_bInjAcvUHReq, TqLimUH_bRlsAltBrkAsi], written-variable=[TqLimUH_bRecupAcv, TqLimUH_bUHRecupInh]
        13 x data receive point:
          dr_CoPt_noGearCord: data-element=R_CoPt_noGearCord.CoPt_noGearCord
          dr_CoPt_stCpl: data-element=R_CoPt_stCpl.CoPt_stCpl
          dr_Eng_nCkFil: data-element=R_Eng_nCkFil.Eng_nCkFil
          dr_CoPtUH_stPwt: data-element=R_CoPtUH_stPwt.CoPtUH_stPwt
          dr_CoVSCtl_rAccPEngTrv: data-element=R_CoVSCtl_rAccPEngTrv.CoVSCtl_rAccPEngTrv
          dr_CoPTSt_stEng: data-element=R_CoPTSt_stEng.CoPTSt_stEng
          dr_Ext_bBrkPedPrss: data-element=R_Ext_bBrkPedPrss.Ext_bBrkPedPrss
          dr_CoOptmEl_stElProd: data-element=R_CoOptmEl_stElProd.CoOptmEl_stElProd
          dr_CoPt_stVoltAltBoostReq: data-element=R_CoPt_stVoltAltBoostReq.CoPt_stVoltAltBoostReq
          dr_CoPt_stCnvCluFil: data-element=R_CoPt_stCnvCluFil.CoPt_stCnvCluFil
          dr_TqSys_nTarIdl: data-element=R_TqSys_nTarIdl.TqSys_nTarIdl
          dr_CoPt_bTqTx: data-element=R_CoPt_bTqTx.CoPt_bTqTx
          dr_TqSys_tqCkEngReal: data-element=R_TqSys_tqCkEngReal.TqSys_tqCkEngReal
        6 x data send point:
          ds_TqLimUH_bfAcvConstFrntTra1: data-element=P_TqLimUH_bfAcvConstFrntTra1.TqLimUH_bfAcvConstFrntTra1
          ds_TqLimUH_stReqBlsVoltCtl: data-element=P_TqLimUH_stReqBlsVoltCtl.TqLimUH_stReqBlsVoltCtl
          ds_TqLimUH_bReqClsCnv: data-element=P_TqLimUH_bReqClsCnv.TqLimUH_bReqClsCnv
          ds_TqLimUH_grdLimVoltCtlDynMax: data-element=P_TqLimUH_grdLimVoltCtlDynMax.TqLimUH_grdLimVoltCtlDynMax
          ds_TqLimUH_stReqUnBlsVoltCtl: data-element=P_TqLimUH_stReqUnBlsVoltCtl.TqLimUH_stReqUnBlsVoltCtl
          ds_TqLimUH_bFrzReqTqVoltCtl: data-element=P_TqLimUH_bFrzReqTqVoltCtl.TqLimUH_bFrzReqTqVoltCtl
        sync call ssp_FRM_bInhRecupVoltCtl: operation=R_FRM_bInhRecupVoltCtl.GetFunctionPermission
        sync call ssp_FRM_bInhRecupUH: operation=R_FRM_bInhRecupUH.GetFunctionPermission
      RE_ProdElEng_014_TEV
        12 x data receive point:
          dr_EOM_stCmbMod: data-element=R_EOM_stCmbMod.EOM_stCmbMod
          dr_CoPt_stDrvTra: data-element=R_CoPt_stDrvTra.CoPt_stDrvTra
          dr_Ext_tAirExtMes: data-element=R_Ext_tAirExtMes.Ext_tAirExtMes
          dr_CoPt_bRvsCord: data-element=R_CoPt_bRvsCord.CoPt_bRvsCord
          dr_Veh_spdVeh: data-element=R_Veh_spdVeh.Veh_spdVeh
          dr_TqSys_tqCkEfcFilTrv: data-element=R_TqSys_tqCkEfcFilTrv.TqSys_tqCkEfcFilTrv
          dr_CoPTSt_stEng: data-element=R_CoPTSt_stEng.CoPTSt_stEng
          dr_Ext_dstVehTotMes: data-element=R_Ext_dstVehTotMes.Ext_dstVehTotMes
          dr_Stg_agStrWhl: data-element=R_Stg_agStrWhl.Stg_agStrWhl
          dr_Ext_nEng: data-element=R_Ext_nEng.Ext_nEng
          dr_Ext_tCoMes: data-element=R_Ext_tCoMes.Ext_tCoMes
          dr_AccP_rAccP: data-element=R_AccP_rAccP.AccP_rAccP
        data send point ds_TqLimUH_stDrivTyp: data-element=P_TqLimUH_stDrivTyp.TqLimUH_stDrivTyp
        sync call ssp_FRM_bDrivTyp: operation=R_FRM_bDrivTyp.GetFunctionPermission
        sync call ssp_FRM_bInhWup: operation=R_FRM_bInhWup.GetFunctionPermission
      RE_ProdElEng_009_MSE: written-variable=[TqSys_bInjFrzTqUHReq, TqSys_bInjAcvUHReq]
      RE_ProdElEng_AftsNvramWrite_1
      RE_ProdElEng_004_TEV: read-variable=[TqSys_bBrioUHAuth, TqLimUH_tqIdcMaxLim, TqLimUH_tqIdcFLdLim], written-variable=[TqLimUH_bBrioUHBoost, TqLimUH_bBrioUHRls, TqLimUH_bBrioUHGrdUnlim, TqLimUH_tqGrdBrioUHJerkLim]
        13 x data receive point:
          dr_AccP_rAccP: data-element=R_AccP_rAccP.AccP_rAccP
          dr_CoPTSt_stEng: data-element=R_CoPTSt_stEng.CoPTSt_stEng
          dr_Ext_bPush: data-element=R_Ext_bPush.Ext_bPush
          dr_TqSys_bDeceAcv: data-element=R_TqSys_bDeceAcv.TqSys_bDeceAcv
          dr_CoPt_noGearCord: data-element=R_CoPt_noGearCord.CoPt_noGearCord
          dr_Veh_spdVeh: data-element=R_Veh_spdVeh.Veh_spdVeh
          dr_TqCmp_tqAltLoss: data-element=R_TqCmp_tqAltLoss.TqCmp_tqAltLoss
          dr_Cha_stTqReq: data-element=R_Cha_stTqReq.Cha_stTqReq
          dr_Eng_nCkFil: data-element=R_Eng_nCkFil.Eng_nCkFil
          dr_CoPt_tqIdcCordLim_tqGBx: data-element=R_CoPt_tqIdcCordLim_tqGBx.CoPt_tqIdcCordLim_tqGBx
          dr_Ext_rCluPHiFreq: data-element=R_Ext_rCluPHiFreq.Ext_rCluPHiFreq
          dr_Ext_stGBxCf: data-element=R_Ext_stGBxCf.Ext_stGBxCf
          dr_CoPt_bRvsCord: data-element=R_CoPt_bRvsCord.CoPt_bRvsCord
        sync call ssp_FRM_bInhTqLimUHBrioUH: operation=R_FRM_bInhTqLimUHBrioUH.GetFunctionPermission
  swc implementation Imp_ProdElEng: programming-language=C, behavior=IB_ProdElEng
    code-descriptors:
      code CodeDescriptor: type=SRC
        36 x xfile:
          ProdElEng_014_calibrations_c: url=ProdElEng_014_calibrations.c
          ProdElEng_006_calibrations_c: url=ProdElEng_006_calibrations.c
          ProdElEng_012_calibrations_c: url=ProdElEng_012_calibrations.c
          ProdElEng_012_TEV_fct_c: url=ProdElEng_012_TEV_fct.c
          ProdElEng_004_TEV_fct_h: url=ProdElEng_004_TEV_fct.h
          ProdElEng_006_TEV_fct_h: url=ProdElEng_006_TEV_fct.h
          ProdElEng_014_calibrations_h: url=ProdElEng_014_calibrations.h
          ProdElEng_004_calibrations_h: url=ProdElEng_004_calibrations.h
          ProdElEng_002_TEV_fct_c: url=ProdElEng_002_TEV_fct.c
          ProdElEng_002_TEV_fct_h: url=ProdElEng_002_TEV_fct.h
          ProdElEng_008_TEV_fct_c: url=ProdElEng_008_TEV_fct.c
          ProdElEng_014_TEV_fct_h: url=ProdElEng_014_TEV_fct.h
          ProdElEng_nvm_c: url=ProdElEng_nvm.c
          ProdElEng_016_TEV_fct_c: url=ProdElEng_016_TEV_fct.c
          ProdElEng_MemMap_h: url=ProdElEng_MemMap.h
          ProdElEng_h: url=ProdElEng.h
          ProdElEng_008_TEV_fct_h: url=ProdElEng_008_TEV_fct.h
          ProdElEng_012_TEV_fct_h: url=ProdElEng_012_TEV_fct.h
          ProdElEng_006_calibrations_h: url=ProdElEng_006_calibrations.h
          ProdElEng_004_TEV_fct_c: url=ProdElEng_004_TEV_fct.c
          ProdElEng_010_TEV_fct_c: url=ProdElEng_010_TEV_fct.c
          ProdElEng_010_TEV_fct_h: url=ProdElEng_010_TEV_fct.h
          ProdElEng_008_calibrations_c: url=ProdElEng_008_calibrations.c
          ProdElEng_014_TEV_fct_c: url=ProdElEng_014_TEV_fct.c
          ProdElEng_010_calibrations_h: url=ProdElEng_010_calibrations.h
          ProdElEng_afts_c: url=ProdElEng_afts.c
          ProdElEng_nvm_h: url=ProdElEng_nvm.h
          ProdElEng_010_calibrations_c: url=ProdElEng_010_calibrations.c
          ProdElEng_006_TEV_fct_c: url=ProdElEng_006_TEV_fct.c
          ProdElEng_016_calibrations_h: url=ProdElEng_016_calibrations.h
          ProdElEng_012_calibrations_h: url=ProdElEng_012_calibrations.h
          ProdElEng_004_calibrations_c: url=ProdElEng_004_calibrations.c
          ProdElEng_c: url=ProdElEng.c
          ProdElEng_016_calibrations_c: url=ProdElEng_016_calibrations.c
          ProdElEng_008_calibrations_h: url=ProdElEng_008_calibrations.h
          ProdElEng_016_TEV_fct_h: url=ProdElEng_016_TEV_fct.h
package /Components/SWC_ProdElEng/ProdElEng_IRVDatatypes
  20 x boolean type, all with base-type=boolean:
    DT_TqLimUH_bAcvAntiStall
    DT_TqLimUH_bAntiStall
    DT_TqLimUH_bAntiStallGrdUnlim
    DT_TqLimUH_bBrioUHBoost
    DT_TqLimUH_bBrioUHGrdUnlim
    DT_TqLimUH_bBrioUHRls
    DT_TqLimUH_bEngUHNOnIdl
    DT_TqLimUH_bESPUnBlsAltReq
    DT_TqLimUH_bOutFrzUHGrdLim
    DT_TqLimUH_bRecupAcv
    DT_TqLimUH_bRlsAltBrkAsi
    DT_TqLimUH_bTqAltFrzReq
    DT_TqLimUH_bUHRecupInh
    DT_TqSys_bBrioUHAuth
    DT_TqSys_bInhRecupUHVoltCtl
    DT_TqSys_bInjAcvUHReq
    DT_TqSys_bInjFrzTqUHReq
    DT_TqSys_bTqAltFrzReq
    DT_TqSys_bTqAltGrdLimReq
    DT_TqSys_bTqAltRlsReq
  4 x integer type:
    DT_TqLimUH_tqGrdBrioUHJerkLim: base-type=uint8, lower-limit=0, upper-limit=255
    DT_TqLimUH_tqGrdLimUHDynMax: base-type=uint8, lower-limit=0, upper-limit=255
    DT_TqLimUH_tqIdcFLdLim: base-type=int16, lower-limit=-32768, upper-limit=32767
    DT_TqLimUH_tqIdcMaxLim: base-type=int16, lower-limit=-32768, upper-limit=32767
